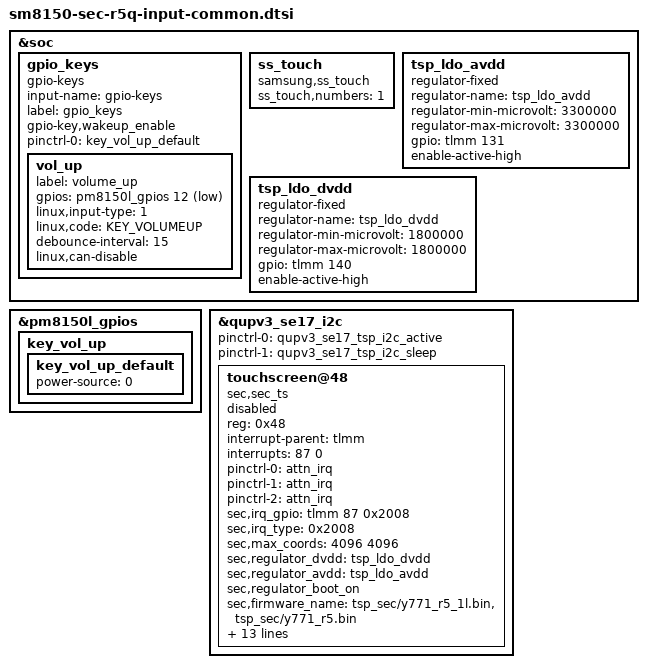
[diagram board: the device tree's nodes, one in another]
/* Copyright (c) 2016-2017, The Linux Foundation. All rights reserved.
 *
 * This program is free software; you can redistribute it and/or modify
 * it under the terms of the GNU General Public License version 2 and
 * only version 2 as published by the Free Software Foundation.
 *
 * This program is distributed in the hope that it will be useful,
 * but WITHOUT ANY WARRANTY; without even the implied warranty of
 * MERCHANTABILITY or FITNESS FOR A PARTICULAR PURPOSE.  See the
 * GNU General Public License for more details.
 */

#include <dt-bindings/input/input.h>

/delete-node/ &gpio_keys;
&soc {
	gpio_keys: gpio_keys {
		status = "ok";
		compatible = "gpio-keys";
		input-name = "gpio-keys";
		label = "gpio_keys";
		gpio-key,wakeup_enable;

		pinctrl-names = "default";
		pinctrl-0 = <&key_vol_up_default>;

		vol_up {
			label = "volume_up";
			gpios = <&pm8150l_gpios 12 GPIO_ACTIVE_LOW>;
			linux,input-type = <1>;
			linux,code = <KEY_VOLUMEUP>;
			debounce-interval = <15>;
			linux,can-disable;
		};
	};

	ss_touch {
		compatible = "samsung,ss_touch";
		ss_touch,numbers = <1>;
	};

	tsp_ldo_avdd {
		compatible = "regulator-fixed";
		regulator-name = "tsp_ldo_avdd";
		regulator-min-microvolt = <3300000>;
		regulator-max-microvolt = <3300000>;
		gpio = <&tlmm 131 0>;
		enable-active-high;
	};

	tsp_ldo_dvdd {
		compatible = "regulator-fixed";
		regulator-name = "tsp_ldo_dvdd";
		regulator-min-microvolt = <1800000>;
		regulator-max-microvolt = <1800000>;
		gpio = <&tlmm 140 0>;
		enable-active-high;
	};
};

&pm8150l_gpios {
	key_vol_up {
		key_vol_up_default: key_vol_up_default {
			power-source = <0>;
		};
	};
};

&qupv3_se17_i2c {
	pinctrl-0 = <&qupv3_se17_tsp_i2c_active>;
	pinctrl-1 = <&qupv3_se17_tsp_i2c_sleep>;
	status = "ok";
	touchscreen@48 {
		status = "disabled";
		compatible = "sec,sec_ts";
		reg = <0x48>;
		interrupt-parent = <&tlmm>;
		interrupts = <87 0>;
		pinctrl-names = "default", "on_state", "off_state";
		pinctrl-0 = <&attn_irq>;
		pinctrl-1 = <&attn_irq>;
		pinctrl-2 = <&attn_irq>;
		sec,irq_gpio = <&tlmm 87 0x2008>;
		sec,irq_type = <0x2008>;
		sec,max_coords = <4096 4096>; /* x y */
		sec,regulator_dvdd = "tsp_ldo_dvdd";
		sec,regulator_avdd = "tsp_ldo_avdd";
		sec,regulator_boot_on;
		sec,firmware_name = "tsp_sec/y771_r5_1l.bin", "tsp_sec/y771_r5.bin";
		sec,tclm_level = <2>;
		sec,afe_base = <0x0209>;
		support_dex_mode;
		sec,i2c-burstmax = <0xffff>;
		sec,ss_touch_num = <1>;
		enable_settings_aot;
		sec,area-size = <132 266 341>;
		support_ear_detect_mode;
		sync-reportrate-120 = "Y";
		support_fod;
		support_fod_gesture;
		support_open_short_test;
		support_mis_calibration_test;
	};
};

